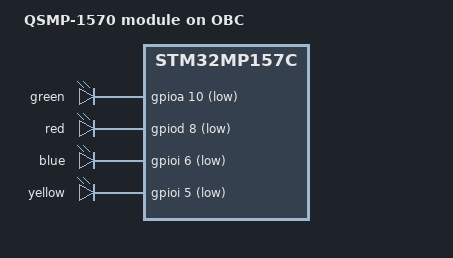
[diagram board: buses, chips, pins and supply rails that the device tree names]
// SPDX-License-Identifier: GPL-2.0 OR BSD-3-Clause
/*
 * Copyright (C) 2021 Martin Schweingruber <martin.schweingruber@schmid-elektronik.ch>
 */


#include "stm32mp157c-qsmp-1570-obc.dtsi"

/ {
	model = "QSMP-1570 module on OBC";
    
	leds {
        compatible = "gpio-leds";
        
        green {
            linux,default-trigger = "none";
            gpios = <&gpioa 10 (GPIO_ACTIVE_LOW | GPIO_PULL_UP)>; /* Pin 77 */
            default-state = "on";
        };

        red {
            linux,default-trigger = "none";
            gpios = <&gpiod 8 (GPIO_ACTIVE_LOW | GPIO_PULL_UP)>; /* Pin 76 */
            default-state = "on";
        };

        blue {
            linux,default-trigger = "none";
            default-state = "on";
            gpios = <&gpioi 6 (GPIO_ACTIVE_LOW | GPIO_PULL_UP)>; /* Pin 75 */
        };

        yellow {
            linux,default-trigger = "none";
            gpios = <&gpioi 5 (GPIO_ACTIVE_LOW | GPIO_PULL_UP)>; /* Pin 74 */
            default-state = "on";
        };

    };
    
};
